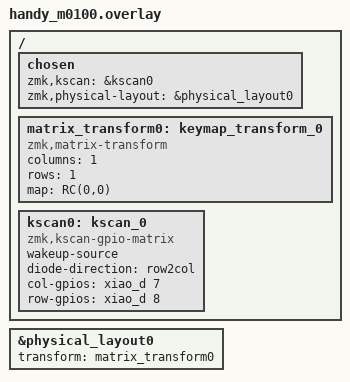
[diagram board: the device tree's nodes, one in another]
/*
 * Copyright (c) 2022 The ZMK Contributors
 *
 * SPDX-License-Identifier: MIT
 */

#include <dt-bindings/zmk/matrix_transform.h>
#include "handy_m0100_layouts.dtsi"

&physical_layout0 {
    transform = <&matrix_transform0>;
};

/ {
    chosen {
        zmk,kscan = &kscan0;
        zmk,physical-layout = &physical_layout0;
    };

    matrix_transform0: keymap_transform_0 {
        compatible = "zmk,matrix-transform";
        columns = <1>;
        rows = <1>;
        map = <
    RC(0,0)
        >;
    };


    kscan0: kscan_0 {
        compatible = "zmk,kscan-gpio-matrix";
        wakeup-source;

        diode-direction = "row2col";

        col-gpios
            = <&xiao_d 7 (GPIO_ACTIVE_HIGH | GPIO_PULL_DOWN)>
            ;

        row-gpios
            = <&xiao_d 8 GPIO_ACTIVE_HIGH>
            ;
    };
};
